AUTOSAR XML (schema 00044)
package /StartApplication/StartApplication_swc/ComponentTypes
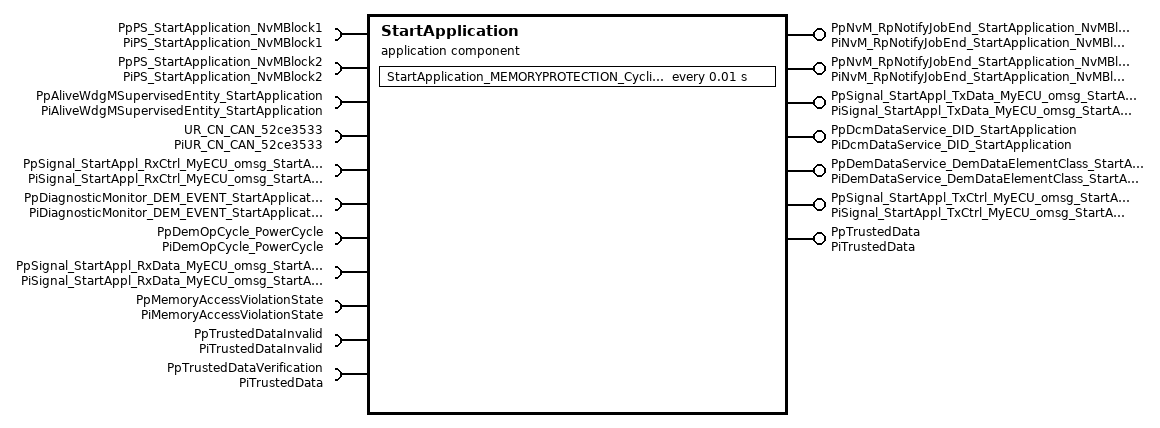
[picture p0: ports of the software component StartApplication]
  application sw component type StartApplication
    provide port PpNvM_RpNotifyJobEnd_StartApplication_NvMBlock1: provided-interface=PiNvM_RpNotifyJobEnd_StartApplication_NvMBlock1
    require port PpPS_StartApplication_NvMBlock1: required-interface=PiPS_StartApplication_NvMBlock1
    provide port PpNvM_RpNotifyJobEnd_StartApplication_NvMBlock2: provided-interface=PiNvM_RpNotifyJobEnd_StartApplication_NvMBlock2
    require port PpPS_StartApplication_NvMBlock2: required-interface=PiPS_StartApplication_NvMBlock2
    require port PpAliveWdgMSupervisedEntity_StartApplication: required-interface=PiAliveWdgMSupervisedEntity_StartApplication
    require port UR_CN_CAN_52ce3533: required-interface=PiUR_CN_CAN_52ce3533
    provide port PpSignal_StartAppl_TxData_MyECU_omsg_StartAppl_Tx_MyECU_oCAN_8c58228b_Tx: nonqueued-sender-com-spec{data-element=DeSignal_StartAppl_TxData_MyECU_omsg_StartAppl_Tx_MyECU_oCAN_8c58228b_Tx, init-value=0}, provided-interface=PiSignal_StartAppl_TxData_MyECU_omsg_StartAppl_Tx_MyECU_oCAN_8c58228b_Tx
    require port PpSignal_StartAppl_RxCtrl_MyECU_omsg_StartAppl_Rx_MyECU_oCAN_09591065_Rx: nonqueued-receiver-com-spec{data-element=DeSignal_StartAppl_RxCtrl_MyECU_omsg_StartAppl_Rx_MyECU_oCAN_09591065_Rx, handle-out-of-range-status=SILENT, init-value=0}, required-interface=PiSignal_StartAppl_RxCtrl_MyECU_omsg_StartAppl_Rx_MyECU_oCAN_09591065_Rx
    require port PpDiagnosticMonitor_DEM_EVENT_StartApplication: required-interface=PiDiagnosticMonitor_DEM_EVENT_StartApplication
    require port PpDemOpCycle_PowerCycle: required-interface=PiDemOpCycle_PowerCycle
    provide port PpDcmDataService_DID_StartApplication: provided-interface=PiDcmDataService_DID_StartApplication
    provide port PpDemDataService_DemDataElementClass_StartApplication: provided-interface=PiDemDataService_DemDataElementClass_StartApplication
    require port PpSignal_StartAppl_RxData_MyECU_omsg_StartAppl_Rx_MyECU_oCAN_315f9453_Rx: nonqueued-receiver-com-spec{data-element=DeSignal_StartAppl_RxData_MyECU_omsg_StartAppl_Rx_MyECU_oCAN_315f9453_Rx, handle-out-of-range-status=SILENT, init-value=0}, required-interface=PiSignal_StartAppl_RxData_MyECU_omsg_StartAppl_Rx_MyECU_oCAN_315f9453_Rx
    provide port PpSignal_StartAppl_TxCtrl_MyECU_omsg_StartAppl_Tx_MyECU_oCAN_b45ea6bd_Tx: nonqueued-sender-com-spec{data-element=DeSignal_StartAppl_TxCtrl_MyECU_omsg_StartAppl_Tx_MyECU_oCAN_b45ea6bd_Tx, init-value=0}, provided-interface=PiSignal_StartAppl_TxCtrl_MyECU_omsg_StartAppl_Tx_MyECU_oCAN_b45ea6bd_Tx
    require port PpMemoryAccessViolationState: required-interface=PiMemoryAccessViolationState
    provide port PpTrustedData: nonqueued-sender-com-spec{data-element=DeValue, init-value=0}, provided-interface=PiTrustedData
    require port PpTrustedDataInvalid: required-interface=PiTrustedDataInvalid
    require port PpTrustedDataVerification: nonqueued-receiver-com-spec{data-element=DeValue, handle-out-of-range-status=SILENT, init-value=0}, required-interface=PiTrustedData
    behavior StartApplicationInternalBehavior: handle-termination-and-restart=NO-SUPPORT
      ar-typed-per-instance-memorys:
        19 x data:
          Uptime: type=uint8
          TxCtrlSigValue: type=uint8
          TxDataSigValue: type=uint8
          ActiveComponent: type=EnumActiveComponentType
          MEM_ActiveBlock: type=uint8
          MEM_DataBuffer1: type=uint8
          MEM_DataBuffer2: type=uint8
          MEM_BlockState1: type=EnumMEM_BlockStateType
          MEM_BlockState2: type=EnumMEM_BlockStateType
          WDG_AliveCycle: type=uint8
          WDG_AliveTimer: type=uint8
          COM_RxSigValue0: type=uint8
          COM_TxSigValue0: type=uint8
          DIAG_LastRxData: type=uint8
          NM_ApplState: type=EnumNM_ApplStateType
          NM_ActiveChannelHasFullComRequest: type=uint8
          NM_BusSleepModeTimer: type=uint8
          NM_ActiveComMChannel: type=uint8
          NM_ActiveComMUsers: type=uint32
      4 x timing event:
        Timer_StartApplication_Cyclic1ms: start-on-event=StartApplication_Cyclic1ms, period=0.001
        Timer_StartApplication_Cyclic10ms: start-on-event=StartApplication_Cyclic10ms, period=0.01
        Timer_StartApplication_Cyclic250ms: start-on-event=StartApplication_Cyclic250ms, period=0.25
        Timer_StartApplication_Cyclic1000ms: start-on-event=StartApplication_Cyclic1000ms, period=1
      init event Timer_StartApplication_Init: start-on-event=StartApplication_Init
      6 x operation invoked event:
        OpEventStartApplication_MEM_JobFinished_StartApplication_NvMBlock1_JobFinished_PpNvM_RpNotifyJobEnd_StartApplication_NvMBlock1: start-on-event=StartApplication_MEM_JobFinished_StartApplication_NvMBlock1, operation=PpNvM_RpNotifyJobEnd_StartApplication_NvMBlock1.JobFinished
        OpEventStartApplication_MEM_JobFinished_StartApplication_NvMBlock2_JobFinished_PpNvM_RpNotifyJobEnd_StartApplication_NvMBlock2: start-on-event=StartApplication_MEM_JobFinished_StartApplication_NvMBlock2, operation=PpNvM_RpNotifyJobEnd_StartApplication_NvMBlock2.JobFinished
        OpEventStartApplication_DIAG_DcmReadData_ReadData_PpDcmDataService_DID_StartApplication: start-on-event=StartApplication_DIAG_DcmReadData, operation=PpDcmDataService_DID_StartApplication.ReadData
        OpEventStartApplication_DIAG_DcmWriteData_WriteData_PpDcmDataService_DID_StartApplication: start-on-event=StartApplication_DIAG_DcmWriteData, operation=PpDcmDataService_DID_StartApplication.WriteData
        OpEventStartApplication_DIAG_ConditionCheckRead_ConditionCheckRead_PpDcmDataService_DID_StartApplication: start-on-event=StartApplication_DIAG_ConditionCheckRead, operation=PpDcmDataService_DID_StartApplication.ConditionCheckRead
        OpEventStartApplication_DIAG_DemReadData_ReadData_PpDemDataService_DemDataElementClass_StartApplication: start-on-event=StartApplication_DIAG_DemReadData, operation=PpDemDataService_DemDataElementClass_StartApplication.ReadData
      data received event DataReceivedEvent_StartApplication_OnDataRec_RxCtrl_PpSignal_StartAppl_RxCtrl_MyECU_omsg_StartAppl_Rx_MyECU_oCAN_095910_3d48f4ff: start-on-event=StartApplication_OnDataRec_RxCtrl, data=PpSignal_StartAppl_RxCtrl_MyECU_omsg_StartAppl_Rx_MyECU_oCAN_09591065_Rx.DeSignal_StartAppl_RxCtrl_MyECU_omsg_StartAppl_Rx_MyECU_oCAN_09591065_Rx
      data received event DataReceivedEvent_StartApplication_OnDataRec_RxData_PpSignal_StartAppl_RxData_MyECU_omsg_StartAppl_Rx_MyECU_oCAN_315f94_d6cb9e1e: start-on-event=StartApplication_OnDataRec_RxData, data=PpSignal_StartAppl_RxData_MyECU_omsg_StartAppl_Rx_MyECU_oCAN_315f9453_Rx.DeSignal_StartAppl_RxData_MyECU_omsg_StartAppl_Rx_MyECU_oCAN_315f9453_Rx
      timing event Timer_StartApplication_MEMORYPROTECTION_Cyclic10ms: start-on-event=StartApplication_MEMORYPROTECTION_Cyclic10ms, period=0.01
      explicit-inter-runnable-variables:
        data IrvOccuranceCounterDid: type=uint16, init-value=0
        data IrvMemoryProtectionData: type=DtMemoryProtectionDataElementType, init-value=fields=[0, 0]
      port-api-options:
        enable-take-address=true, indirect-api=false, port=PpNvM_RpNotifyJobEnd_StartApplication_NvMBlock1
        enable-take-address=true, indirect-api=false, port=PpPS_StartApplication_NvMBlock1
        enable-take-address=true, indirect-api=false, port=PpNvM_RpNotifyJobEnd_StartApplication_NvMBlock2
        enable-take-address=true, indirect-api=false, port=PpPS_StartApplication_NvMBlock2
        enable-take-address=true, indirect-api=false, port=PpAliveWdgMSupervisedEntity_StartApplication
        enable-take-address=true, indirect-api=false, port=UR_CN_CAN_52ce3533
        enable-take-address=true, indirect-api=false, port=PpSignal_StartAppl_TxData_MyECU_omsg_StartAppl_Tx_MyECU_oCAN_8c58228b_Tx
        enable-take-address=true, indirect-api=false, port=PpSignal_StartAppl_RxCtrl_MyECU_omsg_StartAppl_Rx_MyECU_oCAN_09591065_Rx
        enable-take-address=true, indirect-api=false, port=PpDiagnosticMonitor_DEM_EVENT_StartApplication
        enable-take-address=true, indirect-api=false, port=PpDemOpCycle_PowerCycle
        enable-take-address=true, indirect-api=false, port=PpDcmDataService_DID_StartApplication
        enable-take-address=true, indirect-api=false, port=PpDemDataService_DemDataElementClass_StartApplication
        enable-take-address=true, indirect-api=false, port=PpSignal_StartAppl_RxData_MyECU_omsg_StartAppl_Rx_MyECU_oCAN_315f9453_Rx
        enable-take-address=true, indirect-api=false, port=PpSignal_StartAppl_TxCtrl_MyECU_omsg_StartAppl_Tx_MyECU_oCAN_b45ea6bd_Tx
        enable-take-address=true, indirect-api=false, port=PpMemoryAccessViolationState
        enable-take-address=true, indirect-api=false, port=PpTrustedData
        enable-take-address=true, indirect-api=false, port=PpTrustedDataInvalid
        enable-take-address=true, indirect-api=false, port=PpTrustedDataVerification
      14 x runnable:
        StartApplication_Cyclic1ms
        StartApplication_Cyclic10ms
          sync call OpServerCallStartApplication_Cyclic10ms_CheckpointReached_PpAliveWdgMSupervisedEntity_StartApplication: operation=PpAliveWdgMSupervisedEntity_StartApplication.CheckpointReached, timeout=0
        StartApplication_Cyclic250ms
          data-receive-point-by-arguments:
            access DataReceivePointStartApplication_Cyclic250ms_PpSignal_StartAppl_RxCtrl_MyECU_omsg_StartAppl_Rx_MyECU_oCAN_09591065_Rx_D_7ddb12f0: accessed-variable=PpSignal_StartAppl_RxCtrl_MyECU_omsg_StartAppl_Rx_MyECU_oCAN_09591065_Rx.DeSignal_StartAppl_RxCtrl_MyECU_omsg_StartAppl_Rx_MyECU_oCAN_09591065_Rx
            access DataReceivePointStartApplication_Cyclic250ms_PpSignal_StartAppl_RxData_MyECU_omsg_StartAppl_Rx_MyECU_oCAN_315f9453_Rx_D_e2b22488: accessed-variable=PpSignal_StartAppl_RxData_MyECU_omsg_StartAppl_Rx_MyECU_oCAN_315f9453_Rx.DeSignal_StartAppl_RxData_MyECU_omsg_StartAppl_Rx_MyECU_oCAN_315f9453_Rx
            access DataReceivePointStartApplication_Cyclic250ms_PpTrustedDataVerification_DeValue: accessed-variable=PpTrustedDataVerification.DeValue
          data-send-points:
            access DataSendPointStartApplication_Cyclic250ms_PpSignal_StartAppl_TxData_MyECU_omsg_StartAppl_Tx_MyECU_oCAN_8c58228b_Tx_DeSi_19a5c978: accessed-variable=PpSignal_StartAppl_TxData_MyECU_omsg_StartAppl_Tx_MyECU_oCAN_8c58228b_Tx.DeSignal_StartAppl_TxData_MyECU_omsg_StartAppl_Tx_MyECU_oCAN_8c58228b_Tx
            access DataSendPointStartApplication_Cyclic250ms_PpSignal_StartAppl_TxCtrl_MyECU_omsg_StartAppl_Tx_MyECU_oCAN_b45ea6bd_Tx_DeSi_2a62254b: accessed-variable=PpSignal_StartAppl_TxCtrl_MyECU_omsg_StartAppl_Tx_MyECU_oCAN_b45ea6bd_Tx.DeSignal_StartAppl_TxCtrl_MyECU_omsg_StartAppl_Tx_MyECU_oCAN_b45ea6bd_Tx
          read-local-variables:
            access StartApplication_Cyclic250ms_IrvOccuranceCounterDid_DIRECT_READ: accessed-variable=IrvOccuranceCounterDid
          5 x sync call, all with timeout=0:
            OpServerCallStartApplication_Cyclic250ms_ReadBlock_PpPS_StartApplication_NvMBlock1: operation=PpPS_StartApplication_NvMBlock1.ReadBlock
            OpServerCallStartApplication_Cyclic250ms_ReadBlock_PpPS_StartApplication_NvMBlock2: operation=PpPS_StartApplication_NvMBlock2.ReadBlock
            OpServerCallStartApplication_Cyclic250ms_GetCurrentComMode_UR_CN_CAN_52ce3533: operation=UR_CN_CAN_52ce3533.GetCurrentComMode
            OpServerCallStartApplication_Cyclic250ms_RequestComMode_UR_CN_CAN_52ce3533: operation=UR_CN_CAN_52ce3533.RequestComMode
            OpServerCallStartApplication_Cyclic250ms_GetState_PpMemoryAccessViolationState: operation=PpMemoryAccessViolationState.GetState
        StartApplication_Cyclic1000ms
        StartApplication_Init: can-be-invoked-concurrently=true
          sync call OpServerCallStartApplication_Init_RequestComMode_UR_CN_CAN_52ce3533: operation=UR_CN_CAN_52ce3533.RequestComMode, timeout=0
        StartApplication_OnDataRec_RxCtrl
          data-receive-point-by-arguments:
            access DataReceivePointStartApplication_OnDataRec_RxCtrl_PpSignal_StartAppl_RxCtrl_MyECU_omsg_StartAppl_Rx_MyECU_oCAN_09591065_62cc20ae: accessed-variable=PpSignal_StartAppl_RxCtrl_MyECU_omsg_StartAppl_Rx_MyECU_oCAN_09591065_Rx.DeSignal_StartAppl_RxCtrl_MyECU_omsg_StartAppl_Rx_MyECU_oCAN_09591065_Rx
          data-send-points:
            access DataSendPointStartApplication_OnDataRec_RxCtrl_PpSignal_StartAppl_TxCtrl_MyECU_omsg_StartAppl_Tx_MyECU_oCAN_b45ea6bd_Tx_4d900cf4: accessed-variable=PpSignal_StartAppl_TxCtrl_MyECU_omsg_StartAppl_Tx_MyECU_oCAN_b45ea6bd_Tx.DeSignal_StartAppl_TxCtrl_MyECU_omsg_StartAppl_Tx_MyECU_oCAN_b45ea6bd_Tx
          sync call OpServerCallStartApplication_OnDataRec_RxCtrl_SetOperationCycleState_PpDemOpCycle_PowerCycle: operation=PpDemOpCycle_PowerCycle.SetOperationCycleState, timeout=0
        StartApplication_OnDataRec_RxData
          data-receive-point-by-arguments:
            access DataReceivePointStartApplication_OnDataRec_RxData_PpSignal_StartAppl_RxData_MyECU_omsg_StartAppl_Rx_MyECU_oCAN_315f9453_894f4a4f: accessed-variable=PpSignal_StartAppl_RxData_MyECU_omsg_StartAppl_Rx_MyECU_oCAN_315f9453_Rx.DeSignal_StartAppl_RxData_MyECU_omsg_StartAppl_Rx_MyECU_oCAN_315f9453_Rx
          data-send-points:
            access DataSendPointStartApplication_OnDataRec_RxData_PpSignal_StartAppl_TxCtrl_MyECU_omsg_StartAppl_Tx_MyECU_oCAN_b45ea6bd_Tx_397a506d: accessed-variable=PpSignal_StartAppl_TxCtrl_MyECU_omsg_StartAppl_Tx_MyECU_oCAN_b45ea6bd_Tx.DeSignal_StartAppl_TxCtrl_MyECU_omsg_StartAppl_Tx_MyECU_oCAN_b45ea6bd_Tx
            access DataSendPointStartApplication_OnDataRec_RxData_PpTrustedData_DeValue: accessed-variable=PpTrustedData.DeValue
          read-local-variables:
            access StartApplication_OnDataRec_RxData_IrvOccuranceCounterDid_DIRECT_READ: accessed-variable=IrvOccuranceCounterDid
          4 x sync call, all with timeout=0:
            OpServerCallStartApplication_OnDataRec_RxData_WriteBlock_PpPS_StartApplication_NvMBlock1: operation=PpPS_StartApplication_NvMBlock1.WriteBlock
            OpServerCallStartApplication_OnDataRec_RxData_WriteBlock_PpPS_StartApplication_NvMBlock2: operation=PpPS_StartApplication_NvMBlock2.WriteBlock
            OpServerCallStartApplication_OnDataRec_RxData_SetEventStatus_PpDiagnosticMonitor_DEM_EVENT_StartApplication: operation=PpDiagnosticMonitor_DEM_EVENT_StartApplication.SetEventStatus
            OpServerCallStartApplication_OnDataRec_RxData_Reset_PpMemoryAccessViolationState: operation=PpMemoryAccessViolationState.Reset
          written-local-variables:
            access StartApplication_OnDataRec_RxData_IrvOccuranceCounterDid_DIRECT_WRITE: accessed-variable=IrvOccuranceCounterDid
            access StartApplication_OnDataRec_RxData_IrvMemoryProtectionData_DIRECT_WRITE: accessed-variable=IrvMemoryProtectionData
        StartApplication_MEM_JobFinished_StartApplication_NvMBlock1: can-be-invoked-concurrently=true
          data-send-points:
            access DataSendPointStartApplication_MEM_JobFinished_StartApplication_NvMBlock1_PpSignal_StartAppl_TxData_MyECU_omsg_StartAppl_5a982904: accessed-variable=PpSignal_StartAppl_TxData_MyECU_omsg_StartAppl_Tx_MyECU_oCAN_8c58228b_Tx.DeSignal_StartAppl_TxData_MyECU_omsg_StartAppl_Tx_MyECU_oCAN_8c58228b_Tx
            access DataSendPointStartApplication_MEM_JobFinished_StartApplication_NvMBlock1_PpSignal_StartAppl_TxCtrl_MyECU_omsg_StartAppl_695fc537: accessed-variable=PpSignal_StartAppl_TxCtrl_MyECU_omsg_StartAppl_Tx_MyECU_oCAN_b45ea6bd_Tx.DeSignal_StartAppl_TxCtrl_MyECU_omsg_StartAppl_Tx_MyECU_oCAN_b45ea6bd_Tx
        StartApplication_MEM_JobFinished_StartApplication_NvMBlock2: can-be-invoked-concurrently=true
          data-send-points:
            access DataSendPointStartApplication_MEM_JobFinished_StartApplication_NvMBlock2_PpSignal_StartAppl_TxData_MyECU_omsg_StartAppl_feec0f0f: accessed-variable=PpSignal_StartAppl_TxData_MyECU_omsg_StartAppl_Tx_MyECU_oCAN_8c58228b_Tx.DeSignal_StartAppl_TxData_MyECU_omsg_StartAppl_Tx_MyECU_oCAN_8c58228b_Tx
            access DataSendPointStartApplication_MEM_JobFinished_StartApplication_NvMBlock2_PpSignal_StartAppl_TxCtrl_MyECU_omsg_StartAppl_cd2be33c: accessed-variable=PpSignal_StartAppl_TxCtrl_MyECU_omsg_StartAppl_Tx_MyECU_oCAN_b45ea6bd_Tx.DeSignal_StartAppl_TxCtrl_MyECU_omsg_StartAppl_Tx_MyECU_oCAN_b45ea6bd_Tx
        StartApplication_DIAG_DcmReadData: can-be-invoked-concurrently=true
          read-local-variables:
            access StartApplication_DIAG_DcmReadData_IrvOccuranceCounterDid_DIRECT_READ: accessed-variable=IrvOccuranceCounterDid
        StartApplication_DIAG_DcmWriteData: can-be-invoked-concurrently=true
          written-local-variables:
            access StartApplication_DIAG_DcmWriteData_IrvOccuranceCounterDid_DIRECT_WRITE: accessed-variable=IrvOccuranceCounterDid
        StartApplication_DIAG_ConditionCheckRead: can-be-invoked-concurrently=true
        StartApplication_DIAG_DemReadData: can-be-invoked-concurrently=true
          read-local-variables:
            access StartApplication_DIAG_DemReadData_IrvOccuranceCounterDid_DIRECT_READ: accessed-variable=IrvOccuranceCounterDid
        StartApplication_MEMORYPROTECTION_Cyclic10ms
          read-local-variables:
            access StartApplication_MEMORYPROTECTION_Cyclic10ms_IrvMemoryProtectionData_DIRECT_READ: accessed-variable=IrvMemoryProtectionData
          sync call OpServerCallStartApplication_MEMORYPROTECTION_Cyclic10ms_Write_PpTrustedDataInvalid: operation=PpTrustedDataInvalid.Write, timeout=0
          written-local-variables:
            access StartApplication_MEMORYPROTECTION_Cyclic10ms_IrvMemoryProtectionData_DIRECT_WRITE: accessed-variable=IrvMemoryProtectionData
  swc implementation StartApplicationImplementation: programming-language=C, behavior=StartApplicationInternalBehavior
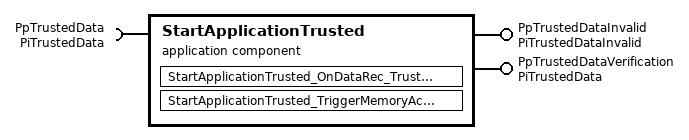
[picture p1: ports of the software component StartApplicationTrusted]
  application sw component type StartApplicationTrusted
    require port PpTrustedData: nonqueued-receiver-com-spec{data-element=DeValue, handle-out-of-range-status=SILENT, init-value=0}, required-interface=PiTrustedData
    provide port PpTrustedDataInvalid: server-com-spec{operation=Write, queue-length=1}, provided-interface=PiTrustedDataInvalid
    provide port PpTrustedDataVerification: nonqueued-sender-com-spec{data-element=DeValue, init-value=0}, provided-interface=PiTrustedData
    behavior StartApplicationTrustedInternalBehavior: handle-termination-and-restart=NO-SUPPORT
      data received event DataReceivedEvent_StartApplicationTrusted_OnDataRec_TrustedData_PpTrustedData_DeValue: start-on-event=StartApplicationTrusted_OnDataRec_TrustedData, data=PpTrustedData.DeValue
      operation invoked event OpEventStartApplicationTrusted_TriggerMemoryAccesViolation_Write_PpTrustedDataInvalid: start-on-event=StartApplicationTrusted_TriggerMemoryAccesViolation, operation=PpTrustedDataInvalid.Write
      explicit-inter-runnable-variables:
        data IrvValue: type=uint8, init-value=0
      port-api-options:
        enable-take-address=true, indirect-api=false, port=PpTrustedData
        enable-take-address=true, indirect-api=false, port=PpTrustedDataInvalid
        enable-take-address=true, indirect-api=false, port=PpTrustedDataVerification
      runnable StartApplicationTrusted_OnDataRec_TrustedData
        data-receive-point-by-arguments:
          access DataReceivePointStartApplicationTrusted_OnDataRec_TrustedData_PpTrustedData_DeValue: accessed-variable=PpTrustedData.DeValue
        data-send-points:
          access DataSendPointStartApplicationTrusted_OnDataRec_TrustedData_PpTrustedDataVerification_DeValue: accessed-variable=PpTrustedDataVerification.DeValue
        read-local-variables:
          access StartApplicationTrusted_OnDataRec_TrustedData_IrvValue_DIRECT_READ: accessed-variable=IrvValue
        written-local-variables:
          access StartApplicationTrusted_OnDataRec_TrustedData_IrvValue_DIRECT_WRITE: accessed-variable=IrvValue
      runnable StartApplicationTrusted_TriggerMemoryAccesViolation
        data-send-points:
          access DataSendPointStartApplicationTrusted_TriggerMemoryAccesViolation_PpTrustedDataVerification_DeValue: accessed-variable=PpTrustedDataVerification.DeValue
        read-local-variables:
          access StartApplicationTrusted_TriggerMemoryAccesViolation_IrvValue_DIRECT_READ: accessed-variable=IrvValue
        written-local-variables:
          access StartApplicationTrusted_TriggerMemoryAccesViolation_IrvValue_DIRECT_WRITE: accessed-variable=IrvValue
  swc implementation StartApplicationTrustedImplementation: programming-language=C, behavior=StartApplicationTrustedInternalBehavior
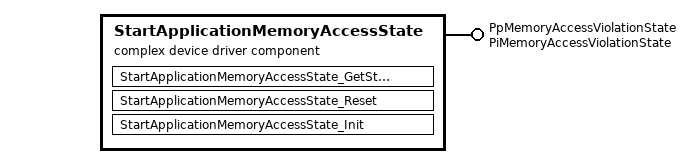
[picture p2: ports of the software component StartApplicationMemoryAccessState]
  complex device driver sw component type StartApplicationMemoryAccessState
    provide port PpMemoryAccessViolationState: provided-com-specs=[{operation=GetState, queue-length=1}, {operation=Reset, queue-length=1}], provided-interface=PiMemoryAccessViolationState
    behavior StartApplicationMemoryAccessStateInternalBehavior: handle-termination-and-restart=NO-SUPPORT, port-api-option{enable-take-address=true, indirect-api=false, port=PpMemoryAccessViolationState}
      ar-typed-per-instance-memorys:
        data PimMemoryAccessState: type=boolean
      operation invoked event OpEventStartApplicationMemoryAccessState_GetState_GetState_PpMemoryAccessViolationState: start-on-event=StartApplicationMemoryAccessState_GetState, operation=PpMemoryAccessViolationState.GetState
      operation invoked event OpEventStartApplicationMemoryAccessState_Reset_Reset_PpMemoryAccessViolationState: start-on-event=StartApplicationMemoryAccessState_Reset, operation=PpMemoryAccessViolationState.Reset
      init event Timer_StartApplicationMemoryAccessState_Init: start-on-event=StartApplicationMemoryAccessState_Init
      runnable StartApplicationMemoryAccessState_GetState
      runnable StartApplicationMemoryAccessState_Reset
      runnable StartApplicationMemoryAccessState_Init: can-be-invoked-concurrently=true
  swc implementation StartApplicationMemoryAccessStateImplementation: programming-language=C, behavior=StartApplicationMemoryAccessStateInternalBehavior
package /StartApplication/StartApplication_swc/DataTypes
  13 x impl type:
    ComM_ModeType: compu {0=COMM_NO_COMMUNICATION, 1=COMM_SILENT_COMMUNICATION, 2=COMM_FULL_COMMUNICATION}, range raw 0..2, implementation-data-type=uint8
    EnumMEM_BlockStateType: compu {0=MEM_STATE_UNKNOWN, 1=MEM_STATE_WRITE_PENDING, 2=MEM_STATE_WRITE_FINISHED, 3=MEM_STATE_READ_PENDING, 4=MEM_STATE_READ_FINISHED, 5=MEM_STATE_WRITE_FAILED, 6=MEM_STATE_READ_FAILED}, range raw 0..6, implementation-data-type=uint8
    NvM_ServiceIdType: compu {6=NVM_READ_BLOCK, 7=NVM_WRITE_BLOCK, 8=NVM_RESTORE_BLOCK_DEFAULTS, 9=NVM_ERASE_BLOCK, 11=NVM_INVALIDATE_NV_BLOCK, 12=NVM_READ_ALL}, range raw 0..12, implementation-data-type=uint8
    NvM_RequestResultType: compu {0=NVM_REQ_OK, 1=NVM_REQ_NOT_OK, 2=NVM_REQ_PENDING, 3=NVM_REQ_INTEGRITY_FAILED, 4=NVM_REQ_BLOCK_SKIPPED, 5=NVM_REQ_NV_INVALIDATED, 6=NVM_REQ_CANCELED, 7=NVM_REQ_REDUNDANCY_FAILED, 8=NVM_REQ_RESTORED_FROM_ROM}, range raw 0..8, implementation-data-type=uint8
    WdgM_CheckpointIdType: implementation-data-type=uint16
    Dem_EventStatusType: compu {0=DEM_EVENT_STATUS_PASSED, 1=DEM_EVENT_STATUS_FAILED, 2=DEM_EVENT_STATUS_PREPASSED, 3=DEM_EVENT_STATUS_PREFAILED, 4=DEM_EVENT_STATUS_FDC_THRESHOLD_REACHED}, range raw 0..4, implementation-data-type=uint8
    Dem_OperationCycleStateType: compu {0=DEM_CYCLE_STATE_START, 1=DEM_CYCLE_STATE_END}, range raw 0..1, implementation-data-type=uint8
    Dcm_Data2ByteType: category=ARRAY, sw-calibration-access=READ-ONLY
      element Dcm_Data2ByteTypeElement: array-size=2, array-size-semantics=FIXED-SIZE, implementation-data-type=uint8
    Dcm_NegativeResponseCodeType:
      compu {0=DCM_E_POSITIVERESPONSE, 16=DCM_E_GENERALREJECT, 17=DCM_E_SERVICENOTSUPPORTED, 18=DCM_E_SUBFUNCTIONNOTSUPPORTED, 19=DCM_E_INCORRECTMESSAGELENGTHORINVALIDFORMAT, 20=DCM_E_RESPONSETOOLONG, 33=DCM_E_BUSYREPEATREQUEST, 34=DCM_E_CONDITIONSNOTCORRECT, 36=DCM_E_REQUESTSEQUENCEERROR, 37=DCM_E_NORESPONSEFROMSUBNETCOMPONENT, 38=DCM_E_FAILUREPREVENTSEXECUTIONOFREQUESTEDACTION, 49=DCM_E_REQUESTOUTOFRANGE, 51=DCM_E_SECURITYACCESSDENIED, 53=DCM_E_INVALIDKEY, 54=DCM_E_EXCEEDNUMBEROFATTEMPTS, 55=DCM_E_REQUIREDTIMEDELAYNOTEXPIRED, 112=DCM_E_UPLOADDOWNLOADNOTACCEPTED, 113=DCM_E_TRANSFERDATASUSPENDED, 114=DCM_E_GENERALPROGRAMMINGFAILURE, 115=DCM_E_WRONGBLOCKSEQUENCECOUNTER, 120=DCM_E_REQUESTCORRECTLYRECEIVEDRESPONSEPENDING, 126=DCM_E_SUBFUNCTIONNOTSUPPORTEDINACTIVESESSION, 127=DCM_E_SERVICENOTSUPPORTEDINACTIVESESSION, 129=DCM_E_RPMTOOHIGH, 130=DCM_E_RPMTOOLOW, 131=DCM_E_ENGINEISRUNNING, 132=DCM_E_ENGINEISNOTRUNNING, 133=DCM_E_ENGINERUNTIMETOOLOW, 134=DCM_E_TEMPERATURETOOHIGH, 135=DCM_E_TEMPERATURETOOLOW, 136=DCM_E_VEHICLESPEEDTOOHIGH, 137=DCM_E_VEHICLESPEEDTOOLOW, 138=DCM_E_THROTTLE_PEDALTOOHIGH, 139=DCM_E_THROTTLE_PEDALTOOLOW, 140=DCM_E_TRANSMISSIONRANGENOTINNEUTRAL, 141=DCM_E_TRANSMISSIONRANGENOTINGEAR, 143=DCM_E_BRAKESWITCH_NOTCLOSED, 144=DCM_E_SHIFTERLEVERNOTINPARK, 145=DCM_E_TORQUECONVERTERCLUTCHLOCKED, 146=DCM_E_VOLTAGETOOHIGH, 147=DCM_E_VOLTAGETOOLOW}
      range raw 0..147
      implementation-data-type=uint8
    DataArray_Type_2: category=ARRAY, sw-calibration-access=READ-ONLY
      element DataArray_Type_2Element: array-size=2, array-size-semantics=FIXED-SIZE, implementation-data-type=uint8
    EnumNM_ApplStateType: compu {0=NM_APPL_STATE_FULL_COMM_EXTERN, 1=NM_APPL_STATE_FULL_COMM_INTERN, 2=NM_APPL_STATE_NO_COMM_EXTERN}, range raw 0..2, implementation-data-type=uint8
    DtMemoryProtectionDataElementType: category=STRUCTURE
      element Value: implementation-data-type=uint8
      element InvalidAccess: implementation-data-type=boolean
    EnumActiveComponentType:
      compu {0=STARTAPPLICATION_ACTIVE_COMPONENT_COM_RXTX, 1=STARTAPPLICATION_ACTIVE_COMPONENT_MEM, 2=STARTAPPLICATION_ACTIVE_COMPONENT_DIAG, 3=STARTAPPLICATION_ACTIVE_COMPONENT_COM_TXONLY, 4=STARTAPPLICATION_ACTIVE_COMPONENT_WDG, 9=STARTAPPLICATION_ACTIVE_COMPONENT_MEMORYPROTECTION, 10=STARTAPPLICATION_ACTIVE_COMPONENT_NM, 255=STARTAPPLICATION_ACTIVE_COMPONENT_INVALID}
      range raw 0..255
      implementation-data-type=uint8
package /StartApplication/StartApplication_swc/Interfaces
  sender receiver interface PiGeneric
    data DeGeneric: type=uint8
  6 x client server interface, all with is-service=true, service-kind=VENDOR-SPECIFIC:
    PiPS_StartApplication_NvMBlock1
      operation WriteBlock: possible-error=PiPS_StartApplication_NvMBlock1/E_NOT_OK
        arg SrcPtr: type=dtRef_const_VOID, direction=IN
      operation ReadBlock: possible-error=PiPS_StartApplication_NvMBlock1/E_NOT_OK
        arg DstPtr: type=dtRef_VOID, direction=IN
      error E_NOT_OK: error-code=1
    PiNvM_RpNotifyJobEnd_StartApplication_NvMBlock1
      operation JobFinished
        arg ServiceId: type=NvM_ServiceIdType, direction=IN
        arg JobResult: type=NvM_RequestResultType, direction=IN
    PiPS_StartApplication_NvMBlock2
      operation WriteBlock: possible-error=PiPS_StartApplication_NvMBlock2/E_NOT_OK
        arg SrcPtr: type=dtRef_const_VOID, direction=IN
      operation ReadBlock: possible-error=PiPS_StartApplication_NvMBlock2/E_NOT_OK
        arg DstPtr: type=dtRef_VOID, direction=IN
      error E_NOT_OK: error-code=1
    PiNvM_RpNotifyJobEnd_StartApplication_NvMBlock2
      operation JobFinished
        arg ServiceId: type=NvM_ServiceIdType, direction=IN
        arg JobResult: type=NvM_RequestResultType, direction=IN
    PiAliveWdgMSupervisedEntity_StartApplication
      operation CheckpointReached: possible-error=PiAliveWdgMSupervisedEntity_StartApplication/E_NOT_OK
        arg checkpointId: type=WdgM_CheckpointIdType, direction=IN
      error E_NOT_OK: error-code=1
    PiUR_CN_CAN_52ce3533
      4 x operation:
        GetCurrentComMode: possible-error=PiUR_CN_CAN_52ce3533/E_NOT_OK
          arg ComMode: type=ComM_ModeType, direction=OUT
        GetMaxComMode: possible-error=PiUR_CN_CAN_52ce3533/E_NOT_OK
          arg ComMode: type=ComM_ModeType, direction=OUT
        GetRequestedComMode: possible-error=PiUR_CN_CAN_52ce3533/E_NOT_OK
          arg ComMode: type=ComM_ModeType, direction=OUT
        RequestComMode: possible-error=[PiUR_CN_CAN_52ce3533/E_NOT_OK, E_MODE_LIMITATION]
          arg ComMode: type=ComM_ModeType, direction=IN
      error E_NOT_OK: error-code=1
      error E_MODE_LIMITATION: error-code=2
  sender receiver interface PiSignal_StartAppl_TxData_MyECU_omsg_StartAppl_Tx_MyECU_oCAN_8c58228b_Tx
    data DeSignal_StartAppl_TxData_MyECU_omsg_StartAppl_Tx_MyECU_oCAN_8c58228b_Tx: type=uint8
  sender receiver interface PiSignal_StartAppl_RxCtrl_MyECU_omsg_StartAppl_Rx_MyECU_oCAN_09591065_Rx
    data DeSignal_StartAppl_RxCtrl_MyECU_omsg_StartAppl_Rx_MyECU_oCAN_09591065_Rx: type=uint8
  4 x client server interface, all with is-service=true, service-kind=VENDOR-SPECIFIC:
    PiDiagnosticMonitor_DEM_EVENT_StartApplication
      operation SetEventStatus: possible-error=PiDiagnosticMonitor_DEM_EVENT_StartApplication/E_NOT_OK
        arg EventStatus: type=Dem_EventStatusType, direction=IN
      operation ResetEventStatus: possible-error=PiDiagnosticMonitor_DEM_EVENT_StartApplication/E_NOT_OK
      error E_NOT_OK: error-code=1
    PiDemOpCycle_PowerCycle
      operation SetOperationCycleState: possible-error=PiDemOpCycle_PowerCycle/E_NOT_OK
        arg CycleState: type=Dem_OperationCycleStateType, direction=IN
      error E_NOT_OK: error-code=1
    PiDcmDataService_DID_StartApplication
      operation WriteData
        arg Data: type=Dcm_Data2ByteType, direction=IN
        arg ErrorCode: type=Dcm_NegativeResponseCodeType, direction=OUT
      operation ReadData
        arg Data: type=Dcm_Data2ByteType, direction=OUT
      operation ConditionCheckRead
        arg ErrorCode: type=Dcm_NegativeResponseCodeType, direction=OUT
    PiDemDataService_DemDataElementClass_StartApplication
      operation ReadData
        arg Data: type=DataArray_Type_2, direction=OUT
  sender receiver interface PiSignal_StartAppl_RxData_MyECU_omsg_StartAppl_Rx_MyECU_oCAN_315f9453_Rx
    data DeSignal_StartAppl_RxData_MyECU_omsg_StartAppl_Rx_MyECU_oCAN_315f9453_Rx: type=uint8
  sender receiver interface PiSignal_StartAppl_TxCtrl_MyECU_omsg_StartAppl_Tx_MyECU_oCAN_b45ea6bd_Tx
    data DeSignal_StartAppl_TxCtrl_MyECU_omsg_StartAppl_Tx_MyECU_oCAN_b45ea6bd_Tx: type=uint8
  client server interface PiMemoryAccessViolationState
    operation GetState
      arg State: type=boolean, direction=OUT
    operation Reset
  sender receiver interface PiTrustedData
    data DeValue: type=uint8
  client server interface PiTrustedDataInvalid
    operation Write
      arg Value: type=uint8, direction=IN
